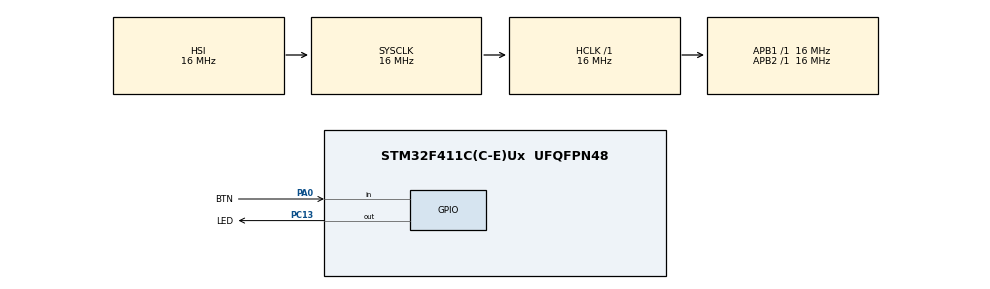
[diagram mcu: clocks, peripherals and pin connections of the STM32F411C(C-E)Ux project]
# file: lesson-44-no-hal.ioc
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Mcu.Family=STM32F4
Mcu.Name=STM32F411C(C-E)Ux
Mcu.Package=UFQFPN48
NVIC.PriorityGroup=NVIC_PRIORITYGROUP_4
PA0-WKUP.GPIO_Label=BTN
PA0-WKUP.GPIO_PuPd=GPIO_PULLUP
PA0-WKUP.Signal=GPIO_Input
PC13-ANTI_TAMP.GPIO_Label=LED
PC13-ANTI_TAMP.Signal=GPIO_Output
ProjectManager.HeapSize=0x200
ProjectManager.StackSize=0x400
ProjectManager.TargetToolchain=STM32CubeIDE
RCC.AHBFreq_Value=16000000
RCC.APB1Freq_Value=16000000
RCC.APB2Freq_Value=16000000
RCC.CortexFreq_Value=16000000
RCC.HSE_VALUE=25000000
RCC.HSI_VALUE=16000000
RCC.LSE_VALUE=32768
RCC.SYSCLKFreq_VALUE=16000000
RCC.VCOOutputFreq_Value=192000000
board=custom

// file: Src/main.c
/* USER CODE BEGIN Header */
/**
  ******************************************************************************
  * @file           : main.c
  * @brief          : Main program body
  ******************************************************************************
  * @attention
  *
  * Copyright (c) 2026 STMicroelectronics.
  * All rights reserved.
  *
  * This software is licensed under terms that can be found in the LICENSE file
  * in the root directory of this software component.
  * If no LICENSE file comes with this software, it is provided AS-IS.
  *
  ******************************************************************************
  */
/* USER CODE END Header */
#include "main.h"

/* USER CODE BEGIN Includes */
#include <limits.h>
#include <stdlib.h>
#include "stm32f411xe.h"
/* USER CODE END Includes */

/* USER CODE BEGIN PD */
/* --- Hardware Constants --- */
#define LED_PIN               13
#define BUTTON_PIN            0

/* --- Register Architecture Constants --- */
#define BITS_PER_PIN_2        2
#define FIELD_MASK_2BIT       3U
#define BSRR_RESET_OFFSET     16
/* USER CODE END PD */

/* USER CODE BEGIN PM */
/* --- GPIO Configuration Macros --- */
#define GPIO_SET_MODE(PORT, PIN, MODE) \
	do { \
			(PORT)->MODER &= ~(FIELD_MASK_2BIT << ((PIN) * BITS_PER_PIN_2)); \
			(PORT)->MODER |=  ((MODE) << ((PIN) * BITS_PER_PIN_2)); \
	} while(0)

/* Clears the 2-bit field and sets the pull-up/down config */
#define GPIO_SET_PUPDR(PORT, PIN, TYPE) \
	do { \
			(PORT)->PUPDR &= ~(FIELD_MASK_2BIT << ((PIN) * BITS_PER_PIN_2)); \
			(PORT)->PUPDR |=  ((TYPE) << ((PIN) * BITS_PER_PIN_2)); \
	} while(0)

/* --- GPIO Actions --- */
#define LED_ON(PORT, PIN)     ((PORT)->BSRR = (1U << ((PIN) + BSRR_RESET_OFFSET)))
#define LED_OFF(PORT, PIN)    ((PORT)->BSRR = (1U << (PIN)))
#define IS_LED_ON(PORT, PIN)  (!((PORT)->ODR & (1U << (PIN))))
#define GET_INPUT(PORT, PIN)  (!((PORT)->IDR & (1U << (PIN)))) // Returns true if LOW (pressed)
/* USER CODE END PM */

void SystemClock_Config(void);
static void MX_GPIO_Init(void);

int main(void)
{

  /* MCU Configuration--------------------------------------------------------*/

  /* Reset of all peripherals, Initializes the Flash interface and the Systick. */
  HAL_Init();

  /* Configure the system clock */
  SystemClock_Config();

  /* Initialize all configured peripherals */
  MX_GPIO_Init();
  /* USER CODE BEGIN 2 */
  /* Enable Clocks */
  RCC->AHB1ENR |= (RCC_AHB1ENR_GPIOAEN | RCC_AHB1ENR_GPIOCEN);

  /* Configure Hardware */
  GPIO_SET_MODE(GPIOC, LED_PIN, GPIO_MODE_OUTPUT_PP);
  GPIO_SET_MODE(GPIOA, BUTTON_PIN, GPIO_MODE_INPUT);
  GPIO_SET_PUPDR(GPIOA, BUTTON_PIN, GPIO_PULLUP);
  /* USER CODE END 2 */

  /* Infinite loop */
  /* USER CODE BEGIN WHILE */
  long rate = 500;
  uint64_t counter = 0;

  while (1)
  {
  	++counter;

  	if (GET_INPUT(GPIOA, BUTTON_PIN)) {
  		if (rate == 500)
  			srandom(HAL_GetTick());
  		rate = (long) (1000.0f * random() / LONG_MAX);
		}
  	if (counter % rate == 0) {
			if (IS_LED_ON(GPIOC, LED_PIN))
				LED_OFF(GPIOC, LED_PIN);
			else
				LED_ON(GPIOC, LED_PIN);
  	}
    /* USER CODE END WHILE */

    /* USER CODE BEGIN 3 */
  	HAL_Delay(1);
  }
  /* USER CODE END 3 */
}

void SystemClock_Config(void)
{
  RCC_OscInitTypeDef RCC_OscInitStruct = {0};
  RCC_ClkInitTypeDef RCC_ClkInitStruct = {0};

  /** Configure the main internal regulator output voltage
  */
  __HAL_RCC_PWR_CLK_ENABLE();
  __HAL_PWR_VOLTAGESCALING_CONFIG(PWR_REGULATOR_VOLTAGE_SCALE1);

  /** Initializes the RCC Oscillators according to the specified parameters
  * in the RCC_OscInitTypeDef structure.
  */
  RCC_OscInitStruct.OscillatorType = RCC_OSCILLATORTYPE_HSI;
  RCC_OscInitStruct.HSIState = RCC_HSI_ON;
  RCC_OscInitStruct.HSICalibrationValue = RCC_HSICALIBRATION_DEFAULT;
  RCC_OscInitStruct.PLL.PLLState = RCC_PLL_NONE;
  if (HAL_RCC_OscConfig(&RCC_OscInitStruct) != HAL_OK)
  {
    Error_Handler();
  }

  /** Initializes the CPU, AHB and APB buses clocks
  */
  RCC_ClkInitStruct.ClockType = RCC_CLOCKTYPE_HCLK|RCC_CLOCKTYPE_SYSCLK
                              |RCC_CLOCKTYPE_PCLK1|RCC_CLOCKTYPE_PCLK2;
  RCC_ClkInitStruct.SYSCLKSource = RCC_SYSCLKSOURCE_HSI;
  RCC_ClkInitStruct.AHBCLKDivider = RCC_SYSCLK_DIV1;
  RCC_ClkInitStruct.APB1CLKDivider = RCC_HCLK_DIV1;
  RCC_ClkInitStruct.APB2CLKDivider = RCC_HCLK_DIV1;

  if (HAL_RCC_ClockConfig(&RCC_ClkInitStruct, FLASH_LATENCY_0) != HAL_OK)
  {
    Error_Handler();
  }
}

static void MX_GPIO_Init(void)
{
  GPIO_InitTypeDef GPIO_InitStruct = {0};
  /* USER CODE BEGIN MX_GPIO_Init_1 */
  return;
  /* USER CODE END MX_GPIO_Init_1 */

  /* GPIO Ports Clock Enable */
  __HAL_RCC_GPIOC_CLK_ENABLE();
  __HAL_RCC_GPIOA_CLK_ENABLE();

  /*Configure GPIO pin Output Level */
  HAL_GPIO_WritePin(LED_GPIO_Port, LED_Pin, GPIO_PIN_RESET);

  /*Configure GPIO pin : LED_Pin */
  GPIO_InitStruct.Pin = LED_Pin;
  GPIO_InitStruct.Mode = GPIO_MODE_OUTPUT_PP;
  GPIO_InitStruct.Pull = GPIO_NOPULL;
  GPIO_InitStruct.Speed = GPIO_SPEED_FREQ_LOW;
  HAL_GPIO_Init(LED_GPIO_Port, &GPIO_InitStruct);

  /*Configure GPIO pin : BTN_Pin */
  GPIO_InitStruct.Pin = BTN_Pin;
  GPIO_InitStruct.Mode = GPIO_MODE_INPUT;
  GPIO_InitStruct.Pull = GPIO_PULLUP;
  HAL_GPIO_Init(BTN_GPIO_Port, &GPIO_InitStruct);

}

void Error_Handler(void)
{
  __disable_irq();
  while (1)
  {
  }
}
